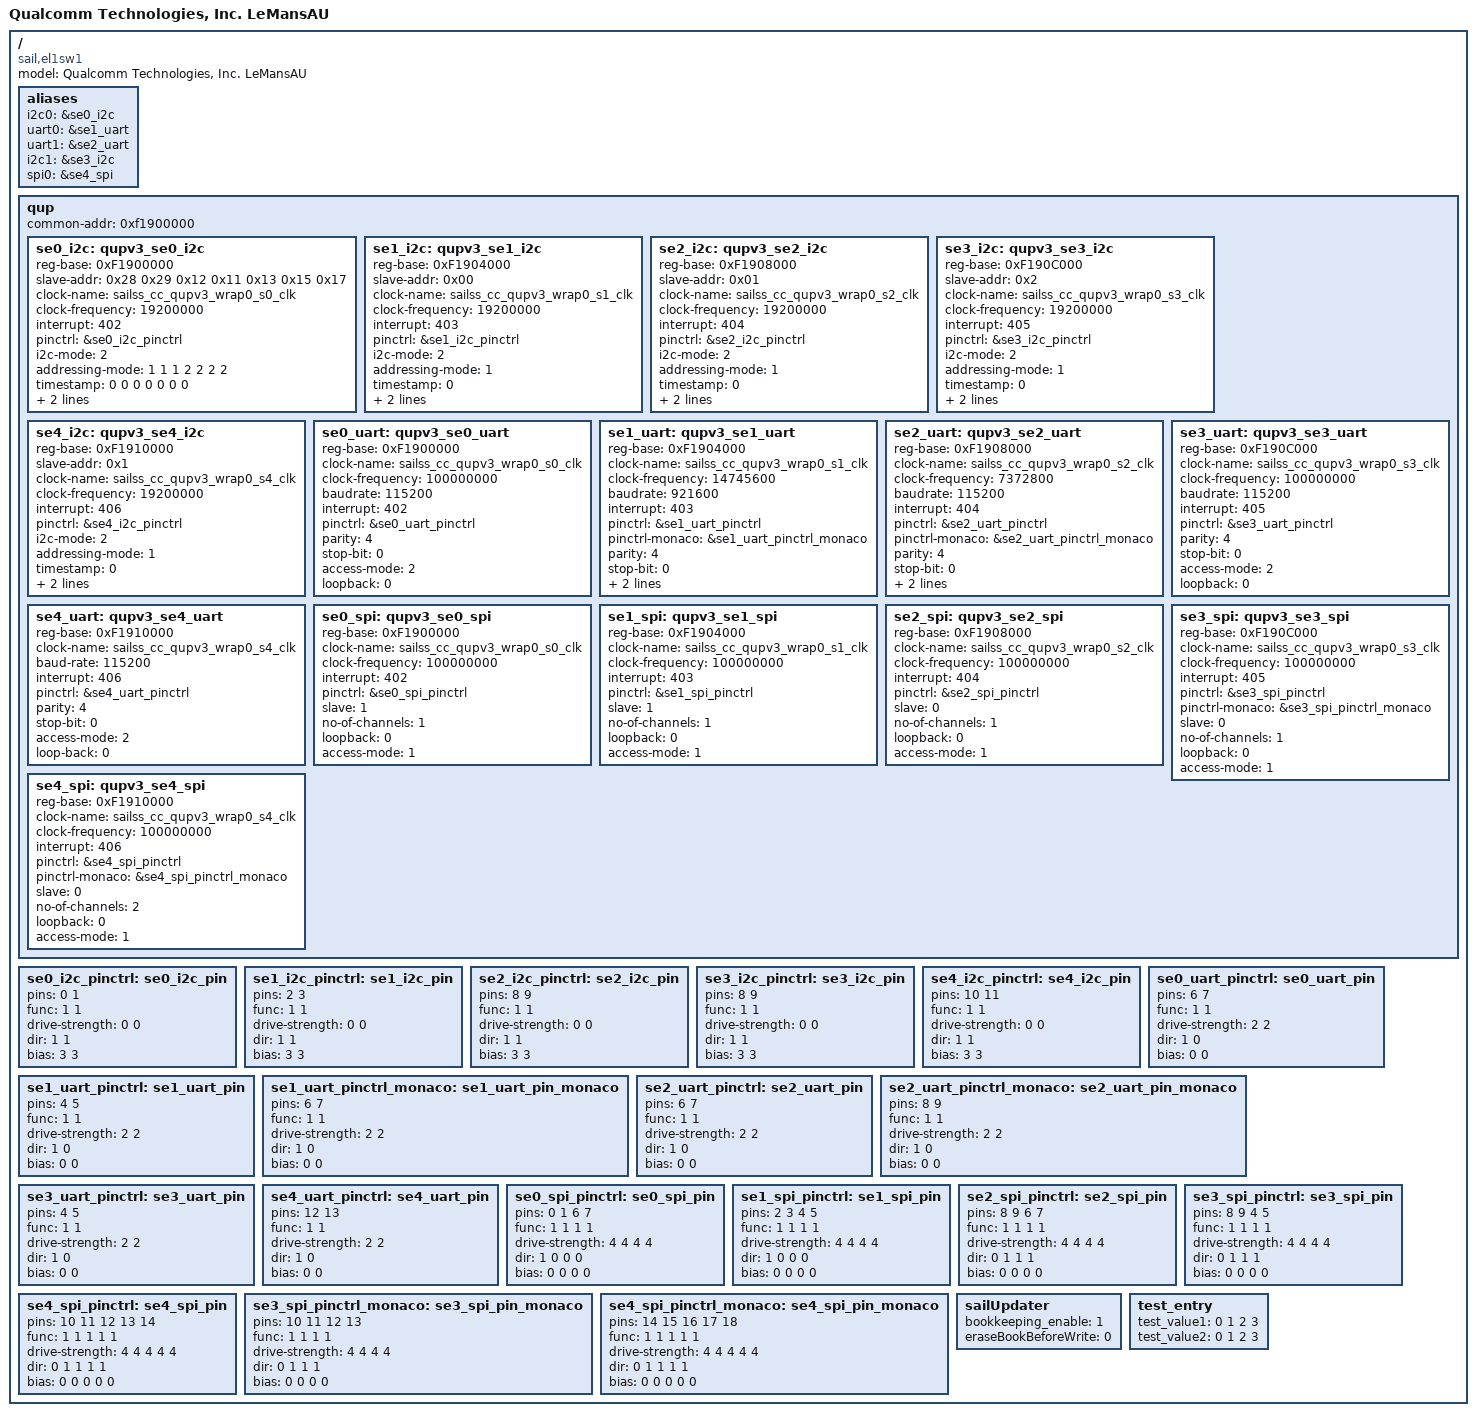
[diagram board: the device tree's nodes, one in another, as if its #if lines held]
/*
 * Copyright (c) 2023-2025 Qualcomm Technologies, Inc.
 * All Rights Reserved.
 * Confidential and Proprietary - Qualcomm Technologies, Inc.
 *
 * Export of this technology or software is regulated by the U.S. Government.
 * Diversion contrary to U.S. law prohibited.
 *
 * All ideas, data and information contained in or disclosed by
 * this document are confidential and proprietary information of
 * Qualcomm Technologies, Inc. and all rights therein are expressly reserved.
 * By accepting this material the recipient agrees that this material
 * and the information contained therein are held in confidence and in
 * trust and will not be used, copied, reproduced in whole or in part,
 * nor its contents revealed in any manner to others without the express
 * written permission of Qualcomm Technologies, Inc.
 */

/dts-v1/;

/ {
    model = "Qualcomm Technologies, Inc. LeMansAU";
    compatible = "sail,el1sw1";

		aliases {
			i2c0 = &se0_i2c;
			uart0 = &se1_uart;
			uart1 = &se2_uart;
			i2c1 = &se3_i2c;
			spi0 = &se4_spi;
	};
	
		qup {
		common-addr = <0xf1900000>;

		/*I2C*/
		se0_i2c: qupv3_se0_i2c {
			reg-base = <0xF1900000>;
			slave-addr = <0x28 0x29 0x12 0x11 0x13 0x15 0x17>;
			clock-name = "sailss_cc_qupv3_wrap0_s0_clk";
			clock-frequency = <19200000>;
			interrupt = <402>;
			pinctrl = &se0_i2c_pinctrl;
			i2c-mode = <2>;
 			addressing-mode = <1 1 1 2 2 2 2>;
 			timestamp = <0 0 0 0 0 0 0>;
			precmd-delay = <0 0 0 0 0 0 0>;
			access-mode = <0>;
			status = <1>;
		};
		
		se1_i2c: qupv3_se1_i2c {
			reg-base = <0xF1904000>;
			slave-addr = <0x00>;
			clock-name = "sailss_cc_qupv3_wrap0_s1_clk";
			clock-frequency = <19200000>;
			interrupt = <403>;
			pinctrl = &se1_i2c_pinctrl;
			i2c-mode = <2>; 
 			addressing-mode = <1>; 
 			timestamp = <0>;
			precmd-delay = <0>;
			access-mode = <0>;
			status = <1>;
		};
		
		se2_i2c: qupv3_se2_i2c {
			reg-base = <0xF1908000>;
			slave-addr = <0x01>;
			clock-name = "sailss_cc_qupv3_wrap0_s2_clk";
			clock-frequency = <19200000>;
			interrupt = <404>;
			pinctrl = &se2_i2c_pinctrl;
			i2c-mode = <2>; 
 			addressing-mode = <1>; 
 			timestamp = <0>;
			precmd-delay = <0>;
			access-mode = <0>;
			status = <1>;
		};
		
		se3_i2c: qupv3_se3_i2c {
			reg-base = <0xF190C000>;
			slave-addr = <0x2>;
			clock-name = "sailss_cc_qupv3_wrap0_s3_clk";
			clock-frequency = <19200000>;
			interrupt = <405>;
			pinctrl = &se3_i2c_pinctrl;
			i2c-mode = <2>; 
 			addressing-mode = <1>;
 			timestamp = <0>;
			precmd-delay = <0>;
			access-mode = <0>;
			status = <1>;
		};
		
		se4_i2c: qupv3_se4_i2c {
			reg-base = <0xF1910000>;
			slave-addr = <0x1>;
			clock-name = "sailss_cc_qupv3_wrap0_s4_clk";
			clock-frequency = <19200000>;
			interrupt = <406>;
			pinctrl = &se4_i2c_pinctrl;
			i2c-mode = <2>;
 			addressing-mode = <1>;
 			timestamp = <0>;
			precmd-delay = <0>;
			access-mode = <0>;
			status = <1>;
		};
		
		/*UART*/
		se0_uart: qupv3_se0_uart {
			reg-base = <0xF1900000>;
			clock-name = "sailss_cc_qupv3_wrap0_s0_clk";
			clock-frequency = <100000000>;
			baudrate = <115200>;
			interrupt = <402>;
			pinctrl = &se0_uart_pinctrl;
			parity = <4>;
			stop-bit = <0>;
			access-mode= <2>;
			loopback  = <0>;
			status = <1>;
		};
		
		se1_uart: qupv3_se1_uart {
			reg-base = <0xF1904000>;
			clock-name = "sailss_cc_qupv3_wrap0_s1_clk";
			clock-frequency = <14745600>;
			baudrate = <921600>;
			interrupt = <403>;
			pinctrl = &se1_uart_pinctrl;
			pinctrl-monaco = &se1_uart_pinctrl_monaco;
			parity = <4>;
			stop-bit = <0>;
			access-mode= <1>;
			loopback  = <0>;
			status = <1>;
		};
		
		se2_uart: qupv3_se2_uart {
			reg-base = <0xF1908000>;
			clock-name = "sailss_cc_qupv3_wrap0_s2_clk";
			clock-frequency = <7372800>;
			baudrate = <115200>;
			interrupt = <404>;
			pinctrl = &se2_uart_pinctrl;
			pinctrl-monaco = &se2_uart_pinctrl_monaco;
			parity = <4>;
			stop-bit = <0>;
			access-mode= <2>;
			loopback  = <0>;
			status = <1>;
		};
		
		se3_uart: qupv3_se3_uart {
			reg-base = <0xF190C000>;
			clock-name = "sailss_cc_qupv3_wrap0_s3_clk";
			clock-frequency = <100000000>;
			baudrate = <115200>;
			interrupt = <405>;
			pinctrl = &se3_uart_pinctrl;
			parity = <4>;
			stop-bit = <0>;
			access-mode= <2>;
			loopback  = <0>;
			status = <1>;
		};
	
		se4_uart: qupv3_se4_uart {
			reg-base = <0xF1910000>;
			clock-name = "sailss_cc_qupv3_wrap0_s4_clk";
			baud-rate = <115200>;
			interrupt = <406>;
			pinctrl = &se4_uart_pinctrl;
			parity = <4>;
			stop-bit = <0>;
			access-mode= <2>;
			loop-back  = <0>;
			status = <1>;
		};
		
		/*SPI*/	
		se0_spi: qupv3_se0_spi {
			reg-base = <0xF1900000>;
			clock-name = "sailss_cc_qupv3_wrap0_s0_clk";
			clock-frequency = <100000000>;
			interrupt = <402>;
			pinctrl = &se0_spi_pinctrl;
			slave = <1>;
			no-of-channels = <1>;
			loopback  = <0>;
			access-mode= <1>;
			status = <1>;
		};
		
		se1_spi: qupv3_se1_spi {
			reg-base = <0xF1904000>;
			clock-name = "sailss_cc_qupv3_wrap0_s1_clk";
			clock-frequency = <100000000>;
			interrupt = <403>;
			pinctrl = &se1_spi_pinctrl;
			slave = <1>;
			no-of-channels = <1>;
			loopback  = <0>;
			access-mode= <1>;
			status = <1>;
		};
		
		se2_spi: qupv3_se2_spi {
			reg-base = <0xF1908000>;
			clock-name = "sailss_cc_qupv3_wrap0_s2_clk";
			clock-frequency = <100000000>;
			interrupt = <404>;
			pinctrl = &se2_spi_pinctrl;
			slave = <0>;
			no-of-channels = <1>;
			loopback  = <0>;
			access-mode= <1>;
			status = <1>;
		};
		
		se3_spi: qupv3_se3_spi {
			reg-base = <0xF190C000>;
			clock-name = "sailss_cc_qupv3_wrap0_s3_clk";
			clock-frequency = <100000000>;
			interrupt = <405>;
			pinctrl = &se3_spi_pinctrl;
			pinctrl-monaco = &se3_spi_pinctrl_monaco;
			slave = <0>;
			no-of-channels = <1>;
			loopback  = <0>;
			access-mode= <1>;
			status = <1>;
		};
		
		se4_spi: qupv3_se4_spi {
			reg-base = <0xF1910000>;
			clock-name = "sailss_cc_qupv3_wrap0_s4_clk";
			clock-frequency = <100000000>;
			interrupt = <406>;
			pinctrl = &se4_spi_pinctrl;
			pinctrl-monaco = &se4_spi_pinctrl_monaco;
			slave = <0>;
			no-of-channels = <2>;
			loopback  = <0>;
			access-mode= <1>;
			status = <1>;
		};
	};
	
	/*I2C Pincontrol*/
	se0_i2c_pinctrl: se0_i2c_pin{
			pins = < 0 1 >; 
			func = < 1 1>; 
			drive-strength = < 0 0>; 
			dir = < 1 1>; 
			bias = < 3 3>; 	
	};
	
	se1_i2c_pinctrl: se1_i2c_pin{
			pins = < 2 3 >; 
			func = < 1 1>; 
			drive-strength = < 0 0>; 
			dir = < 1 1>; 
			bias = < 3 3>; 	
	};
	
	se2_i2c_pinctrl: se2_i2c_pin{
			pins = < 8 9 >; 
			func = < 1 1>; 
			drive-strength = < 0 0>; 
			dir = < 1 1>; 
			bias = < 3 3>; 	
	};
	
	se3_i2c_pinctrl: se3_i2c_pin{
			pins = < 8 9 >; 
			func = < 1 1>; 
			drive-strength = < 0 0>; 
			dir = < 1 1>; 
			bias = < 3 3>; 	
	};
	
	se4_i2c_pinctrl: se4_i2c_pin{
			pins = < 10 11 >; 
			func = < 1 1>; 
			drive-strength = < 0 0>; 
			dir = < 1 1>; 
			bias = < 3 3>; 	
	};
	
	/*UART Pincontrol*/
	se0_uart_pinctrl: se0_uart_pin{
			pins = < 6 7 >;
			func = < 1 1>; 
			drive-strength = < 2 2>; 
			dir = < 1 0>; 
			bias = < 0 0>; 	
	};
	
	se1_uart_pinctrl: se1_uart_pin{
			pins = < 4 5 >; //tx - rx - cts - rts
			func = < 1 1>; 
			drive-strength = < 2 2>; 
			dir = < 1 0>; 
			bias = < 0 0>; 	
	};

	se1_uart_pinctrl_monaco: se1_uart_pin_monaco{
			pins = < 6 7 >; //tx - rx - cts - rts
			func = < 1 1>; 
			drive-strength = < 2 2>; 
			dir = < 1 0>; 
			bias = < 0 0>; 	
	};
		
	se2_uart_pinctrl: se2_uart_pin{
			pins = < 6 7>;
			func = < 1 1>; 
			drive-strength = < 2 2>; 
			dir = < 1 0>; 
			bias = < 0 0>; 	
	};

	se2_uart_pinctrl_monaco: se2_uart_pin_monaco{
			pins = < 8 9>;
			func = < 1 1>; 
			drive-strength = < 2 2>; 
			dir = < 1 0>; 
			bias = < 0 0>; 	
	};
	
	se3_uart_pinctrl: se3_uart_pin{
			pins = < 4 5 >;
			func = < 1 1>; 
			drive-strength = < 2 2>; 
			dir = < 1 0>; 
			bias = < 0 0>; 	
	};
	
	se4_uart_pinctrl: se4_uart_pin{
			pins = < 12 13 >;
			func = < 1 1>; 
			drive-strength = < 2 2>; 
			dir = < 1 0>; 
			bias = < 0 0>; 	
	};
	
	/*SPI Pincontrol*/
	se0_spi_pinctrl: se0_spi_pin{
			pins = < 0 1 6 7>; //miso mosi sclk cs0
			func = < 1 1 1 1 >; 
			drive-strength = < 4 4 4 4 >;
			dir = < 1 0 0 0 >; 
			bias = < 0 0 0 0 >; 	
	};
	
	se1_spi_pinctrl: se1_spi_pin{
			pins = < 2 3 4 5>; //miso mosi sclk cs0
			func = < 1 1 1 1 >; 
			drive-strength = < 4 4 4 4 >;
			dir = < 1 0 0 0 >; 
			bias = < 0 0 0 0 >; 	
	};
	
	se2_spi_pinctrl: se2_spi_pin{
			pins = < 8 9 6 7>; //miso mosi sclk cs0
			func = < 1 1 1 1 >; 
			drive-strength = < 4 4 4 4 >;
			dir = < 0 1 1 1 >; 
			bias = < 0 0 0 0 >; 	
	};
	
	se3_spi_pinctrl: se3_spi_pin{
			pins = < 8 9 4 5>; //miso mosi sclk cs0
			func = < 1 1 1 1 >; 
			drive-strength = < 4 4 4 4 >;
			dir = < 0 1 1 1 >; 
			bias = < 0 0 0 0 >; 	
	};
	
	se4_spi_pinctrl: se4_spi_pin{
			pins = < 10 11 12 13 14>; //miso mosi sclk cs0 cs1
			func = < 1 1 1 1 1>; 
			drive-strength = < 4 4 4 4 4>; 
			dir = < 0 1 1 1 1>; 
			bias = < 0 0 0 0 0>;		
	};
	
	se3_spi_pinctrl_monaco: se3_spi_pin_monaco{
			pins = < 10 11 12 13>; //miso mosi sclk cs0
			func = < 1 1 1 1 >; 
			drive-strength = < 4 4 4 4 >;
			dir = < 0 1 1 1 >; 
			bias = < 0 0 0 0 >; 	
	};
	
	se4_spi_pinctrl_monaco: se4_spi_pin_monaco{
			pins = < 14 15 16 17 18>; //miso mosi sclk cs0 cs1
			func = < 1 1 1 1 1>; 
			drive-strength = < 4 4 4 4 4>; 
			dir = < 0 1 1 1 1>; 
			bias = < 0 0 0 0 0>;		
	};

	sailUpdater {
                    bookkeeping_enable = <1>;
                    eraseBookBeforeWrite = <0>; //Erase bookkeeping partition everytime before write
        };
    /* place this test entry at the last of DTS file for perf test */
    test_entry {
        test_value1 = <0 1 2 3>;
        test_value2 = <0 1 2 3>;
    };
};

#ifdef CONFIG1
/include/ "config1.dtsi"
#endif /* CONFIG1 */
